# HC32A4A8RITJ register map
File version: 1.0
CPU: CM4 r0p1, little endian, MPU, FPU, 4 interrupt priority bits
Registers are 32-bit, read-write, reset 0x0 unless marked. A register's access mark holds for its fields unless they carry their own. Offsets are from the block's base; [hi:lo] are bit positions; {n}, {i} and the like mark numbered series; 'fields as' and 'values as' point back to an identical list.

## GPIO
Base 0x40053800
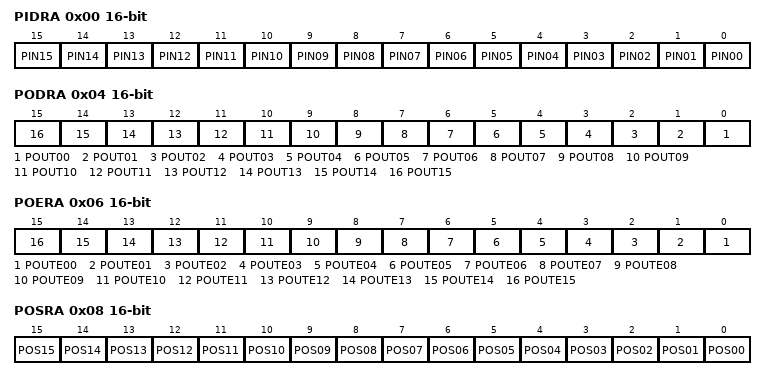
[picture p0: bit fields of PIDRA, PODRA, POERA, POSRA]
0x00 PIDRA 16-bit ro
  [n] PIN{n:02} (n=0..15)
0x04 PODRA 16-bit
  [n] POUT{n:02} (n=0..15)
0x06 POERA 16-bit
  [n] POUTE{n:02} (n=0..15)
0x08 POSRA 16-bit wo
  [n] POS{n:02} (n=0..15)
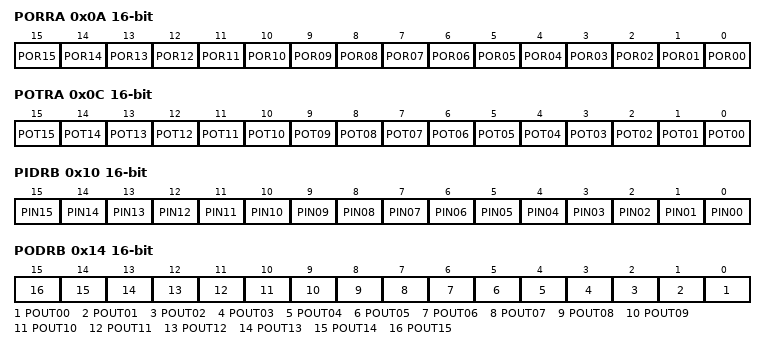
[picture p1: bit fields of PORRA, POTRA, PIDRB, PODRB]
0x0A PORRA 16-bit wo
  [n] POR{n:02} (n=0..15)
0x0C POTRA 16-bit wo
  [n] POT{n:02} (n=0..15)
0x10 PIDRB 16-bit ro
  [n] PIN{n:02} (n=0..15)
0x14 PODRB 16-bit
  [n] POUT{n:02} (n=0..15)
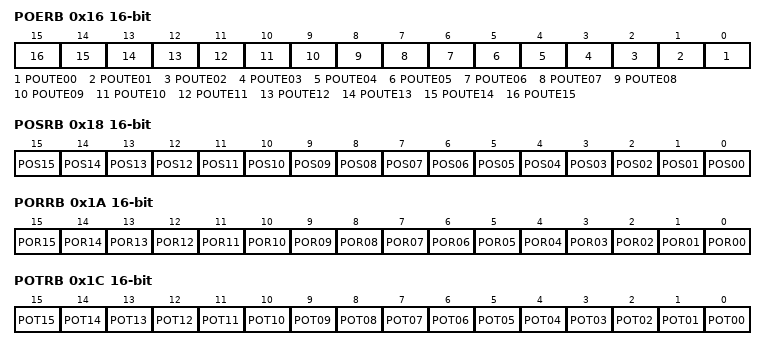
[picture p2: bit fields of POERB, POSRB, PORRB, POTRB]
0x16 POERB 16-bit
  [n] POUTE{n:02} (n=0..15)
0x18 POSRB 16-bit wo
  [n] POS{n:02} (n=0..15)
0x1A PORRB 16-bit wo
  [n] POR{n:02} (n=0..15)
0x1C POTRB 16-bit wo
  [n] POT{n:02} (n=0..15)
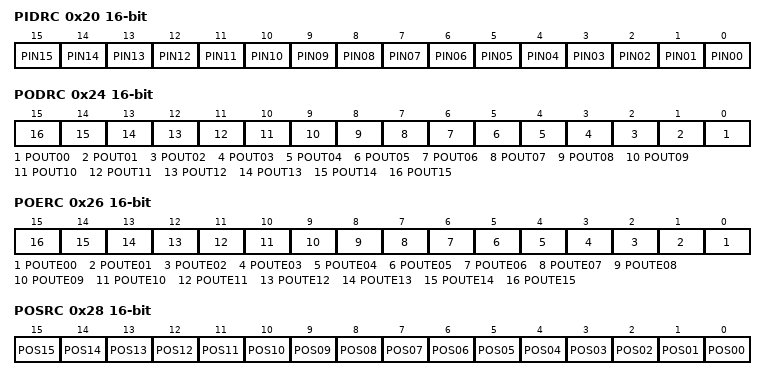
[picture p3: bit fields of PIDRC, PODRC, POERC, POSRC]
0x20 PIDRC 16-bit ro
  [n] PIN{n:02} (n=0..15)
0x24 PODRC 16-bit
  [n] POUT{n:02} (n=0..15)
0x26 POERC 16-bit
  [n] POUTE{n:02} (n=0..15)
0x28 POSRC 16-bit wo
  [n] POS{n:02} (n=0..15)
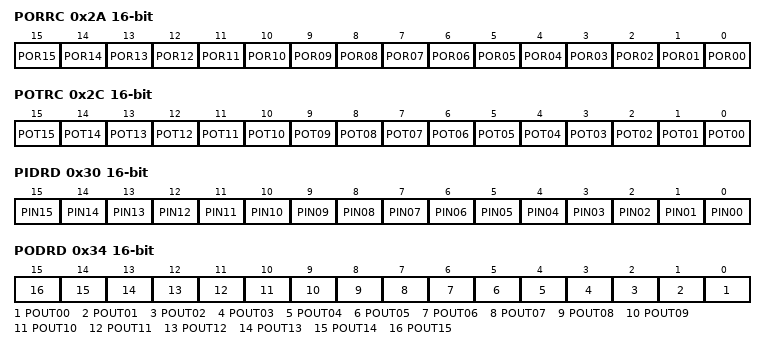
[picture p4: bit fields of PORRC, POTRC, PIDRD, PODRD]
0x2A PORRC 16-bit wo
  [n] POR{n:02} (n=0..15)
0x2C POTRC 16-bit wo
  [n] POT{n:02} (n=0..15)
0x30 PIDRD 16-bit ro
  [n] PIN{n:02} (n=0..15)
0x34 PODRD 16-bit
  [n] POUT{n:02} (n=0..15)
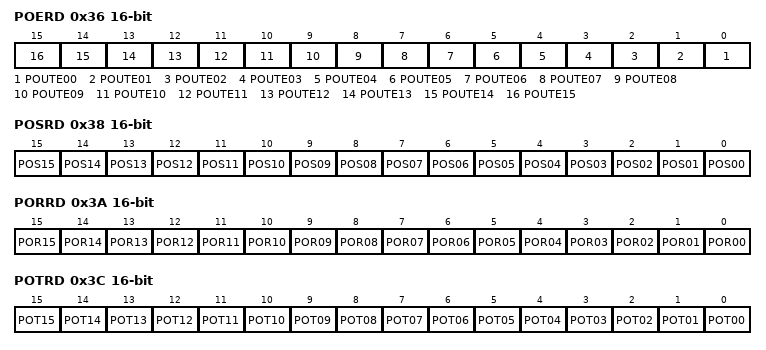
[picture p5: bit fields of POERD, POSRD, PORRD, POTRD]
0x36 POERD 16-bit
  [n] POUTE{n:02} (n=0..15)
0x38 POSRD 16-bit wo
  [n] POS{n:02} (n=0..15)
0x3A PORRD 16-bit wo
  [n] POR{n:02} (n=0..15)
0x3C POTRD 16-bit wo
  [n] POT{n:02} (n=0..15)
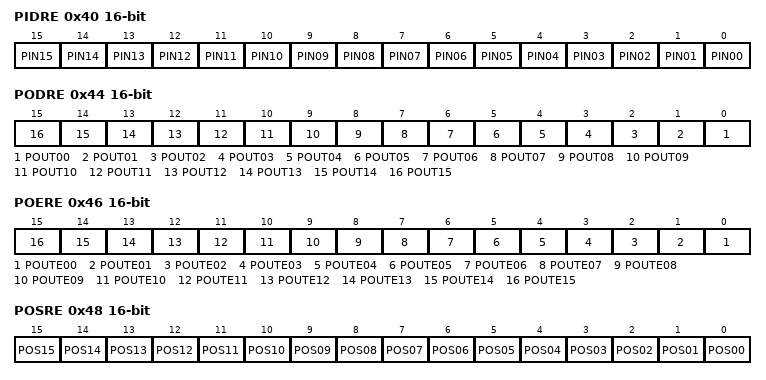
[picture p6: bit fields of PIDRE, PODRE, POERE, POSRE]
0x40 PIDRE 16-bit ro
  [n] PIN{n:02} (n=0..15)
0x44 PODRE 16-bit
  [n] POUT{n:02} (n=0..15)
0x46 POERE 16-bit
  [n] POUTE{n:02} (n=0..15)
0x48 POSRE 16-bit wo
  [n] POS{n:02} (n=0..15)
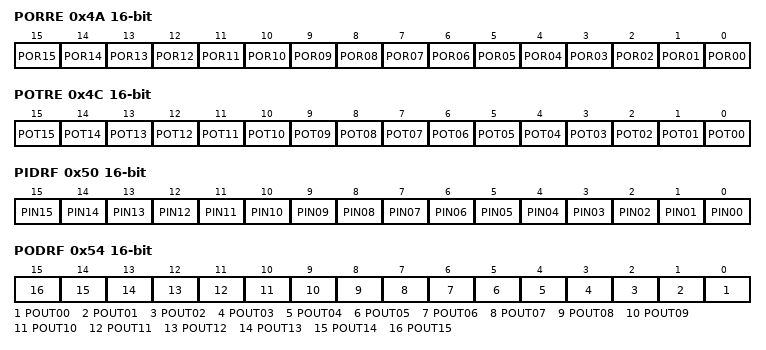
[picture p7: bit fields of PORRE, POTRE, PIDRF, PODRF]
0x4A PORRE 16-bit wo
  [n] POR{n:02} (n=0..15)
0x4C POTRE 16-bit wo
  [n] POT{n:02} (n=0..15)
0x50 PIDRF 16-bit ro
  [n] PIN{n:02} (n=0..15)
0x54 PODRF 16-bit
  [n] POUT{n:02} (n=0..15)
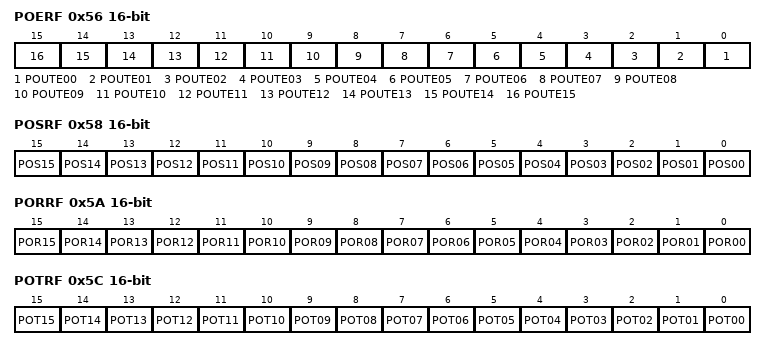
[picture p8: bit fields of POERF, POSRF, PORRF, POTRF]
0x56 POERF 16-bit
  [n] POUTE{n:02} (n=0..15)
0x58 POSRF 16-bit wo
  [n] POS{n:02} (n=0..15)
0x5A PORRF 16-bit wo
  [n] POR{n:02} (n=0..15)
0x5C POTRF 16-bit wo
  [n] POT{n:02} (n=0..15)
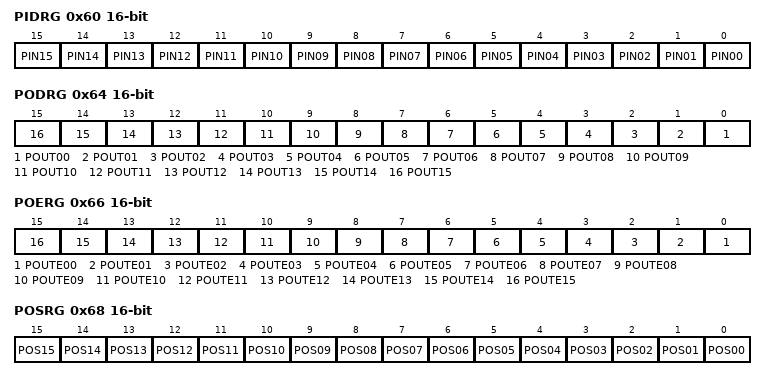
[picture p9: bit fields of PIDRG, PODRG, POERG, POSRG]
0x60 PIDRG 16-bit ro
  [n] PIN{n:02} (n=0..15)
0x64 PODRG 16-bit
  [n] POUT{n:02} (n=0..15)
0x66 POERG 16-bit
  [n] POUTE{n:02} (n=0..15)
0x68 POSRG 16-bit wo
  [n] POS{n:02} (n=0..15)
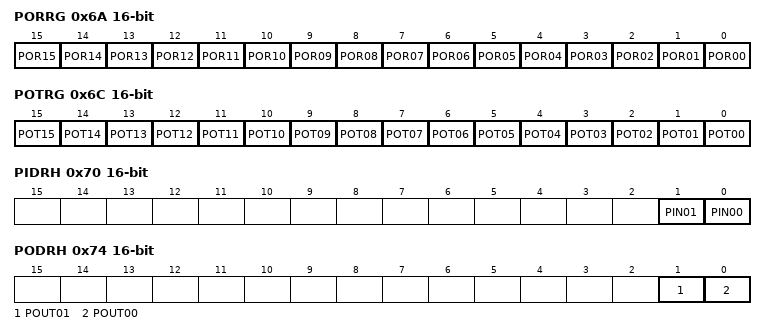
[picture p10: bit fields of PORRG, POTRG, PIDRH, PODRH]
0x6A PORRG 16-bit wo
  [n] POR{n:02} (n=0..15)
0x6C POTRG 16-bit wo
  [n] POT{n:02} (n=0..15)
0x70 PIDRH 16-bit ro
  [1] PIN01, [0] PIN00
0x74 PODRH 16-bit
  [1] POUT01, [0] POUT00
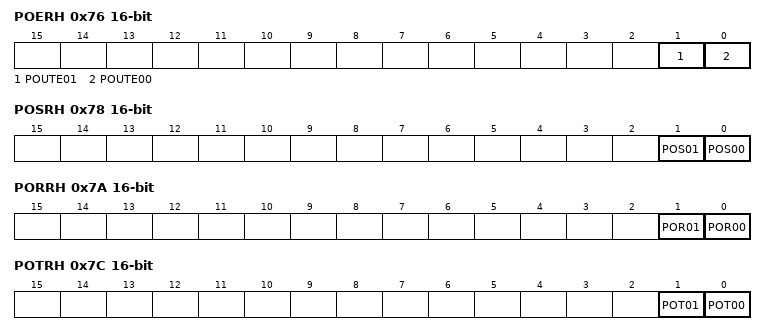
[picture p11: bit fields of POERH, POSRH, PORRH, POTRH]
0x76 POERH 16-bit
  [1] POUTE01, [0] POUTE00
0x78 POSRH 16-bit wo
  [1] POS01, [0] POS00
0x7A PORRH 16-bit wo
  [1] POR01, [0] POR00
0x7C POTRH 16-bit wo
  [1] POT01, [0] POT00
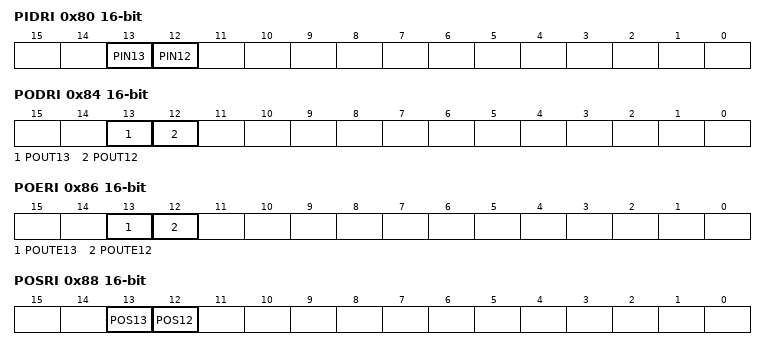
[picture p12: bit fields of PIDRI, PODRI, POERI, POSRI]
0x80 PIDRI 16-bit ro
  [13] PIN13, [12] PIN12
0x84 PODRI 16-bit
  [13] POUT13, [12] POUT12
0x86 POERI 16-bit
  [13] POUTE13, [12] POUTE12
0x88 POSRI 16-bit wo
  [13] POS13, [12] POS12
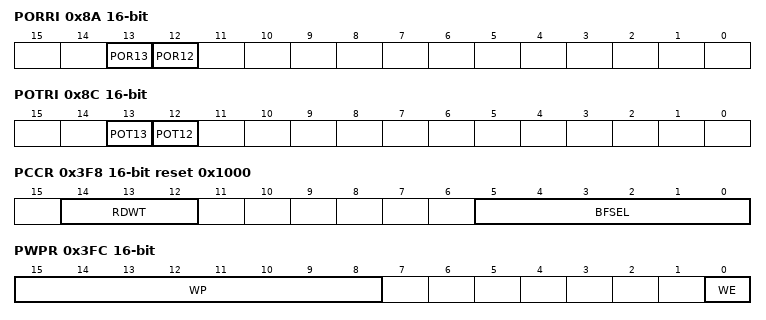
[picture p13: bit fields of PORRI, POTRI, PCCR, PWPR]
0x8A PORRI 16-bit wo
  [13] POR13, [12] POR12
0x8C POTRI 16-bit wo
  [13] POT13, [12] POT12
0x3F4 PSPCR 16-bit reset 0x1F
  [4:0] SPFE
0x3F8 PCCR 16-bit reset 0x1000
  [14:12] RDWT, [5:0] BFSEL
0x3FA PINAER 16-bit
  [8:0] PINAE
0x3FC PWPR 16-bit
  [15:8] WP wo, [0] WE
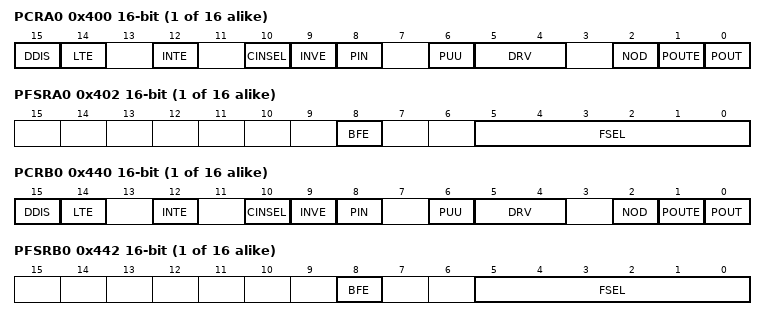
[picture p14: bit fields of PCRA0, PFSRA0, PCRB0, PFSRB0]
{0x400+4i} PCRA{i} 16-bit (i=0..15)
  [15] DDIS, [14] LTE, [12] INTE, [10] CINSEL, [9] INVE, [8] PIN ro, [6] PUU, [5:4] DRV, [2] NOD, [1] POUTE, [0] POUT
{0x402+4i} PFSRA{i} 16-bit (i=0..15)
  [8] BFE, [5:0] FSEL
{0x440+4i} PCRB{i} 16-bit (i=0..15)
  fields as PCRA0
{0x442+4i} PFSRB{i} 16-bit (i=0..15)
  [8] BFE, [5:0] FSEL
{0x480+4i} PCRC{i} 16-bit (i=0..13)
  fields as PCRA0
{0x482+4i} PFSRC{i} 16-bit (i=0..15)
  [8] BFE, [5:0] FSEL
0x4B8 PCRC14 16-bit reset 0x8100
  fields as PCRA0
0x4BC PCRC15 16-bit reset 0x8100
  fields as PCRA0
{0x4C0+4i} PCRD{i} 16-bit (i=0..15)
  fields as PCRA0
{0x4C2+4i} PFSRD{i} 16-bit (i=0..15)
  [8] BFE, [5:0] FSEL
{0x500+4i} PCRE{i} 16-bit (i=0..15)
  fields as PCRA0
{0x502+4i} PFSRE{i} 16-bit (i=0..15)
  [8] BFE, [5:0] FSEL
{0x540+4i} PCRF{i} 16-bit (i=0..15)
  fields as PCRA0
{0x542+4i} PFSRF{i} 16-bit (i=0..15)
  [8] BFE, [5:0] FSEL
{0x580+4i} PCRG{i} 16-bit (i=0..15)
  fields as PCRA0
{0x582+4i} PFSRG{i} 16-bit (i=0..15)
  [8] BFE, [5:0] FSEL
0x5C0 PCRH0 16-bit
  fields as PCRA0
0x5C2 PFSRH0 16-bit
  [8] BFE, [5:0] FSEL
0x5C4 PCRH1 16-bit
  fields as PCRA0
0x5C6 PFSRH1 16-bit
  [8] BFE, [5:0] FSEL
0x630 PCRI12 16-bit
  fields as PCRA0
0x632 PFSRI12 16-bit
  [8] BFE, [5:0] FSEL
0x634 PCRI13 16-bit
  fields as PCRA0
0x636 PFSRI13 16-bit
  [8] BFE, [5:0] FSEL
